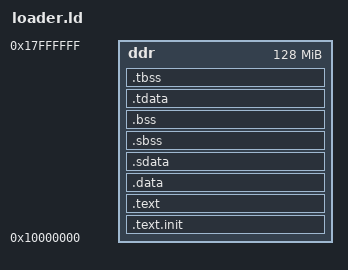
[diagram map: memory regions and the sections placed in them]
/*======================================================================*/
/* Proxy kernel linker script                                           */
/*======================================================================*/
/* This is the linker script used when building the proxy kernel. */

/*----------------------------------------------------------------------*/
/* Setup                                                                */
/*----------------------------------------------------------------------*/

/* The OUTPUT_ARCH command specifies the machine architecture where the
   argument is one of the names used in the BFD library. More
   specifically one of the entires in bfd/cpu-mips.c */

OUTPUT_ARCH( "riscv" )
ENTRY(_start)

MEMORY {
  ddr : ORIGIN = 0x10000000, LENGTH = 128M
}

/*----------------------------------------------------------------------*/
/* Sections                                                             */
/*----------------------------------------------------------------------*/

SECTIONS
{

  /* text: test code section */
  /* . = 0x80000000; */
  .text.init : { *(.text.init) } > ddr

  .text : { *(.text) } > ddr

  /* data segment */
  .data : { *(.data) } > ddr

  .sdata : {
    __global_pointer$ = . + 0x800;
    *(.srodata.cst16) *(.srodata.cst8) *(.srodata.cst4) *(.srodata.cst2) *(.srodata*)
    *(.sdata .sdata.* .gnu.linkonce.s.*)
  } > ddr

  /* bss segment */
  .sbss : {
    *(.sbss .sbss.* .gnu.linkonce.sb.*)
    *(.scommon)
  } > ddr
  .bss : { *(.bss) } > ddr

  /* thread-local data segment */
  .tdata :
  {
    _tls_data = .;
    *(.tdata.begin)
    *(.tdata)
    *(.tdata.end)
  } > ddr
  .tbss :
  {
    *(.tbss)
    *(.tbss.end)
  } > ddr

  /* End of uninitalized data segement */
  _end = .;
}
